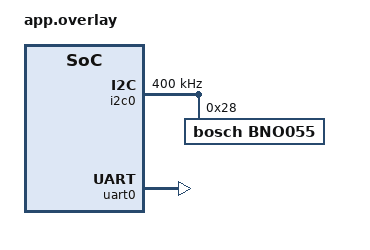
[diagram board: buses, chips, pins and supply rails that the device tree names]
&i2c0 {
    status ="ok";
    clock-frequency = <I2C_BITRATE_FAST>;

    bno055@28 {
		status = "okay";
		compatible = "bosch,bno055";
		reg = <0x28>;
		model = "bno055";

	};

};


&uart0 {
	status = "okay";
	hw-flow-control;
};
